# TZ10xx register map
File version: 0.1g
Registers are 32-bit, read-write, reset 0x0 unless marked. A register's access mark holds for its fields unless they carry their own. Offsets are from the block's base; [hi:lo] are bit positions.

## uart0
Base 0x40064000
Same registers: uart1 0x40065000, uart2 0x40070000
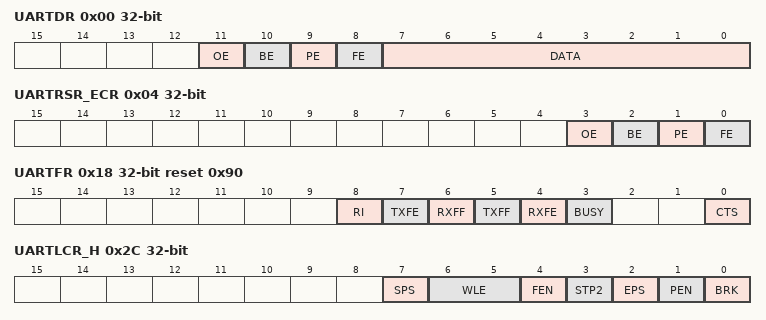
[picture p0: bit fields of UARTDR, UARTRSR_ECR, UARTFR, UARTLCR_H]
0x00 UARTDR — UART Data Register
  [11] OE ro — Overrun error 0b1: Error occurrence If FIFO is full of data at data reception and reception data becomes ready to be stored, 0b1 is stored at next FIFO fetching. The data stored in FIFO remains unchanged and reception data in the shift register used before FIFO storing is overwritten. 0b0: No error If FIFO becomes ready to store data, 0b0 is stored at next FIFO fetching.
  [10] BE ro — Break error 0b1: Error occurrence Indicates that the break condition was detected (break status: Low input equal to or greater than "reception data + status bit). In FIFO mode, 0b1 is set when the reception data for which that condition was generated comes to the highest stage. The reception data after the break condition was detected is subject to marking (High status acceptance), resulting in a wait for the next start bit detection. 0b0: No error
  [9] PE ro — Parity error 0b1: Error occurrence If the reception data does not satisfy the configured parity condition, 0b1 is set. In FIFO mode, 0b1 is set when the reception data for which that condition was generated comes to the highest stage. 0b0: No error
  [8] FE ro — Framing error 0b1: Error occurrence If the reception data does not satisfy the configured stop bit length, 0b1 is set. In FIFO mode, 0b1 is set when the reception data for which that condition was generated comes to the highest stage. 0b0: No error
  [7:0] DATA — Send and receive data At reading: Data of reception FIFO is read. At writing: Data is written to transmission FIFO. (Note) If transmission or reception is disabled midway, it stops after current data transfer is complete.
0x04 UARTRSR_ECR — UART Receive status Register/Error clear Register
  [3] OE — At reading: Overrun error 0b1: Error occurrence 0b0: No error At writing: The error flag can be cleared by writing to this register, regardless of the data value.
  [2] BE — At reading: Break error 0b1: Error occurrence 0b0: No error At writing: The error flag can be cleared by writing to this register, regardless of the data value.
  [1] PE — At reading: Parity error 0b1: Error occurrence 0b0: No error At writing: The error flag can be cleared by writing to this register, regardless of the data value.
  [0] FE — At reading: Framing error 0b1: Error occurrence 0b0: No error At writing: The error flag can be cleared by writing to this register, regardless of the data value.
0x18 UARTFR ro reset 0x90 — UART Flag Register
  [8] RI — (Ring Indicator) nUARTRI terminal status 0b1:nUARTRI = Low input status 0b0:nUARTRI = High input status
  [7] TXFE — Transmission FIFO Empty 0b1: Transmission FIFO empty (FIFO mode)/transmission retention register empty (FIFO disable) 0b0: Data existence in transmission FIFO (FIFO mode)/data existence in the transmission retention register (FIFO disable)
  [6] RXFF — Reception FIFO Full 0b1: Reception FIFO full of data (FIFO mode)/reception retention register full of data (FIFO disable) 0b0: Reception FIFO not full of data (FIFO mode)/reception retention register not full of data(FIFO disable)
  [5] TXFF — Transmission FIFO Full 0b1: Transmission FIFO full of data (FIFO mode)/transmission retention register full of data (FIFO disable) 0b0: Transmission FIFO not full of data (FIFO mode)/transmission retention register not full of data(FIFO disable)
  [4] RXFE — Reception FIFO Empty 0b1: Reception FIFO empty (FIFO mode)/reception retention register empty (FIFO disable) 0b0: Data existence in reception FIFO (FIFO mode)/data existence in the reception retention register (FIFO disable)
  [3] BUSY — Busy status 0b1: Data transmission in progress 0b0: Idle status without transmission data
  [0] CTS — nUARTCTS terminal status (Clear To Send) 0b1:nUARTCTS =Low input status 0b0:nUARTCTS =High input status
0x24 UARTIBRD — UART Integer part of the Baud Rate Divisor Register
  [15:0] BAUD_DIVINT — For baud rate generation (integer value)
0x28 UARTFBRD — UART Fractional part of the Baud Rate Divisor Register
  [5:0] BAUD_DIVFRAC — For baud rate generation (fractional value) The baud rate divisor can be obtained as follows: Baud rate divisor BAUDDIV =(FUARTCLK/(16 * baud rate) FUARTCLK is a UART reference clock frequency. BAUDDIV consists of an integer value (BAUD DIVINT) and fractional value (BAUD DIVFRAC). (Note) Transmission and reception operations are disabled if both BAUD DIVINT and BAUD DIVFRAC are set to 0x00.
0x2C UARTLCR_H — UART Line control register
  [7] SPS — Stick parity selection 0b1: Enable With PEN=1, EPS=0, and SPS=1, transmission or reception is checked with parity bit =1. With PEN=1, EPS=1, and SPS=1, transmission or reception is checked with parity bit =0. 0b0: Disable
  [6:5] WLE — Transfer bit length 0b11: 8-bit length 0b10: 7-bit length 0b01: 6-bit length 0b00: 5-bit length
  [4] FEN — FIFO enable 0b1: Enable. FIFO mode is entered. 0b0: Disable
  [3] STP2 — Stop bit length selection 0b1: 2-bit length 0b0: 1-bit length
  [2] EPS — Even parity selection 0b1: Even parity 0b0: Odd parity
  [1] PEN — Parity enable 0b1: Enable 0b0: Disable
  [0] BRK — Break transmission 0b1:Break transmission 0b0: Normal transmission (Note) Data needs to be written in the following order in setting the UARTTIBRD, UARTTFBRD, and UARTLCR_H registers. UARTLCR_H writing should be done last. (Example 1) UARTIBRD writing, UARTFBRD writing, UARTLCR_H writing (Example 2) UARTFBRD writing, UARTIBRD writing, UARTLCR_H writing
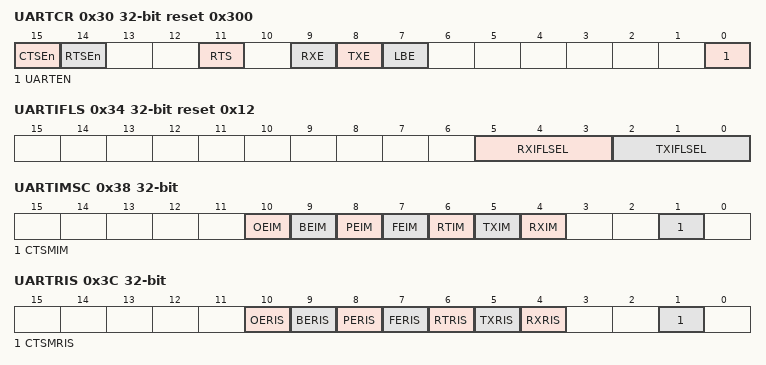
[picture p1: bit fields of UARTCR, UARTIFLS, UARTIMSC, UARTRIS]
0x30 UARTCR reset 0x300 — UART Control Register
  [15] CTSEn — CTS hardware flow control 0b1: Enable. Data is not transmitted until the nUARTCTS signal is asserted. 0b0: Disable
  [14] RTSEn — RTS hardware flow control 0b1: Enable. Data is requested only when reception FIFO contains space for receiving that data. 0b0: Disable
  [11] RTS — nUARTRTS output control 0b1:nUARTRTS=Low output 0b0:nUARTRTS=High output
  [9] RXE — Reception enable 0b1: Enable. If reception is disabled midway, it stops after data being currently received has been received. 0b0: Disable
  [8] TXE — Transmission enable 0b1: Enable. If transmission is disabled midway, it stops after data being currently transmitted has been transmitted. 0b0: Disable
  [7] LBE — Loopback enable 0b1: Enable 0b0: Disable
  [0] UARTEN — UART enable 0b1: Enable. If transmission or reception is disabled midway, it stops after completing the current transmission or reception processing. 0b0: Disable
0x34 UARTIFLS reset 0x12 — UART Interrupt FIFO Level Select Register
  [5:3] RXIFLSEL — Reception interrupt FIFO level selection (trigger occurs when FIFO becomes equal to or greater than the setting level.) 0b111 - 0b101:reserved 0b100: Reception FIFO>= 7/8 Full 0b011: Reception FIFO>= 3/4 Full 0b010: Reception FIFO>= 1/2 Full 0b001: Reception FIFO>= 1/4 Full 0b000: Reception FIFO>= 1/8 Full
  [2:0] TXIFLSEL — Transmission interrupt FIFO level selection (trigger occurs when FIFO becomes equal to or less than the setting level.) 0b111 - 0b101:reserved 0b100: Transmission FIFO<= 7/8 Full 0b011: Transmission FIFO<= 3/4 Full 0b010: Transmission FIFO<= 1/2 Full 0b001: Transmission FIFO<= 1/4 Full 0b000: Transmission FIFO<= 1/8 Full (Note) For UART, the 16byte FIFO is configured. So, each FIFO level indicates the following size. 1/8 Full = 2byte, 1/4 Full = 4byte, 1/2 Full = 8byte, 3/4 Full = 12byte, 7/8 Full = 14byte
0x38 UARTIMSC — UART Interrupt Mask Set/Clear
  [10] OEIM — Overrun error interrupt 0b1: No interrupt mask (interrupt enable) 0b0: Interrupt mask (interrupt disable)
  [9] BEIM — Break error interrupt 0b1: No interrupt mask (interrupt enable) 0b0: Interrupt mask (interrupt disable)
  [8] PEIM — Parity error interrupt 0b1: No interrupt mask (interrupt enable) 0b0: Interrupt mask (interrupt disable)
  [7] FEIM — Framing error interrupt 0b1: No interrupt mask (interrupt enable) 0b0: Interrupt mask (interrupt disable)
  [6] RTIM — Reception timeout interrupt 0b1: No interrupt mask (interrupt enable) 0b0: Interrupt mask (interrupt disable)
  [5] TXIM — Transmission interrupt 0b1: No interrupt mask (interrupt enable) 0b0: Interrupt mask (interrupt disable)
  [4] RXIM — Reception interrupt 0b1: No interrupt mask (interrupt enable) 0b0: Interrupt mask (interrupt disable)
  [1] CTSMIM — nUARTCTS modem interrupt 0b1: No interrupt mask (interrupt enable) 0b0: Interrupt mask (interrupt disable)
0x3C UARTRIS ro — UART Raw Interrupt Status Register
  [10] OERIS — Overrun error interrupt 0b1: Interrupt request available (UART interrupt occurrence before masking) 0b0: No interrupt request (UART interrupt occurrence before masking)
  [9] BERIS — Break error interrupt 0b1: Interrupt request available (UART interrupt occurrence before masking) 0b0: No interrupt request (UART interrupt occurrence before masking)
  [8] PERIS — Parity error interrupt 0b1: Interrupt request available (UART interrupt occurrence before masking) 0b0: No interrupt request (UART interrupt occurrence before masking)
  [7] FERIS — Framing error interrupt 0b1: Interrupt request available (UART interrupt occurrence before masking) 0b0: No interrupt request (UART interrupt occurrence before masking)
  [6] RTRIS — Reception timeout interrupt 0b1: Interrupt request available (UART interrupt occurrence before masking) 0b0: No interrupt request (UART interrupt occurrence before masking) (Note) Unlike other bits, RTRIS does not become 0b1 until RTIM=1 is set.
  [5] TXRIS — Transmission interrupt 0b1: Interrupt request available (UART interrupt occurrence before masking) 0b0: No interrupt request (UART interrupt occurrence before masking)
  [4] RXRIS — Reception interrupt 0b1: Interrupt request available (UART interrupt occurrence before masking) 0b0: No interrupt request (UART interrupt occurrence before masking)
  [1] CTSMRIS — nUARTCTS modem interrupt 0b1: Interrupt request available (UART interrupt occurrence before masking) 0b0: No interrupt (UART interrupt occurrence before masking) The value depends on wire connection. An interrupt request occurs every time the signal state changes.
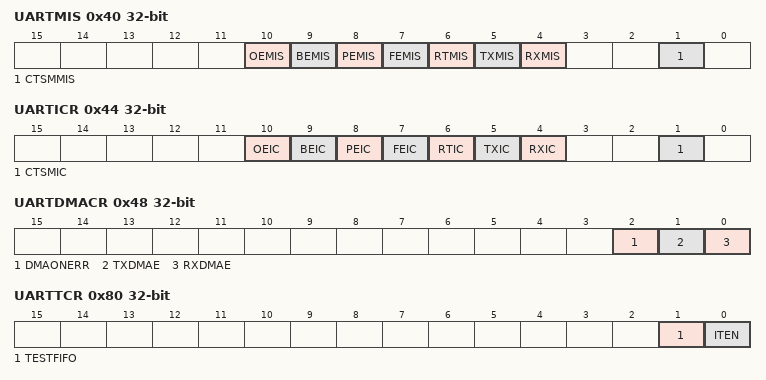
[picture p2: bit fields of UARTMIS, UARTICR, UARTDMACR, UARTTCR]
0x40 UARTMIS ro — UART Masked Interrupt Status Register
  [10] OEMIS — Overrun error interrupt
  [9] BEMIS — Break error interrupt
  [8] PEMIS — Parity error interrupt
  [7] FEMIS — Framing error interrupt
  [6] RTMIS — Reception timeout interrupt
  [5] TXMIS — Transmission interrupt
  [4] RXMIS — Reception interrupt
  [1] CTSMMIS — nUARTCTS modem interrupt
0x44 UARTICR — UART Interrupt Clear Register
  [10] OEIC — Overrun error interrupt 0b1: Interrupt request clear 0b0: No operation
  [9] BEIC — Break error interrupt 0b1: Interrupt request clear 0b0: No operation
  [8] PEIC — Parity error interrupt 0b1: Interrupt request clear 0b0: No operation
  [7] FEIC — Framing error interrupt 0b1: Interrupt request clear 0b0: No operation
  [6] RTIC — Reception timeout interrupt 0b1: Interrupt request clear 0b0: No operation
  [5] TXIC — Transmission interrupt 0b1: Interrupt request clear 0b0: No operation
  [4] RXIC — Reception interrupt 0b1: Interrupt request clear 0b0: No operation
  [1] CTSMIC — nUARTCTS modem interrupt 0b1: Interrupt request clear 0b0: No operation
0x48 UARTDMACR — UART DMA Control Register
  [2] DMAONERR — DMA on Error 0b1: Disables the DMA request if UART generates Error interrupt. 0b0: Normal operation
  [1] TXDMAE — Transmission FIFO DMA enable 0b1: DMA request enable 0b0: No DMA request
  [0] RXDMAE — Reception FIFO DMA enable 0b1: DMA request enable 0b0: No DMA request
0x80 UARTTCR — UART Test Control Register
  [1] TESTFIFO — Test FIFO enable 0b1: Test mode 0b0: Normal operation
  [0] ITEN — Integration test enable 0b1: Test mode 0b0: Normal operation
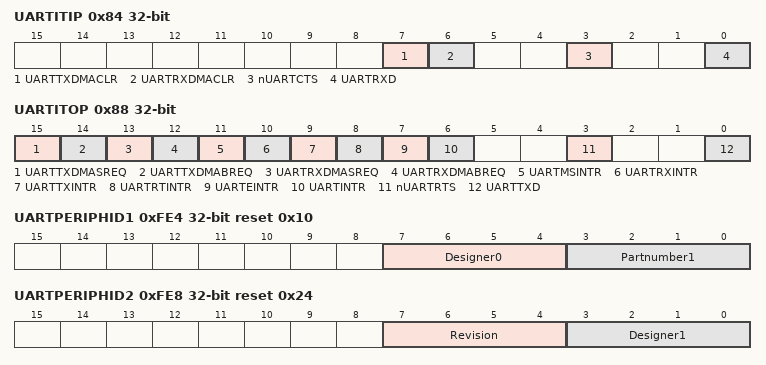
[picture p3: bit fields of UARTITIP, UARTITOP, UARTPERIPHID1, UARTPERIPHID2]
0x84 UARTITIP — UART Integration Test InPut Register
  [7] UARTTXDMACLR — AT writing, output to the UARTTXDMACLR terminal At reading, reading of the UARTTXDMACLR terminal status
  [6] UARTRXDMACLR — AT writing, output to the UARTRXDMACLR terminal At reading, reading of the UARTRXDMACLR terminal status
  [3] nUARTCTS ro — At reading, reads the nUARTCTS terminal status.
  [0] UARTRXD ro — At reading, reads the UARTRXD terminal status.
0x88 UARTITOP — UART Integration Test OutPut Register
  [15] UARTTXDMASREQ — At writing, makes output to the UARTTXDMASREQ terminal. At reading, reads the UARTTXDMASREQ terminal status.
  [14] UARTTXDMABREQ — At writing, makes output to the UARTTXDMABREQ terminal. At reading, reads the UARTTXDMABREQ terminal status.
  [13] UARTRXDMASREQ — At writing, makes output to the UARTRXDMASREQ terminal. At reading, reads the UARTRXDMASREQ terminal status.
  [12] UARTRXDMABREQ — At writing, makes output to the UARTRXDMABREQ terminal. At reading, reads the UARTRXDMABREQ terminal status.
  [11] UARTMSINTR — At writing, makes output to the UARTMSINTR terminal. At reading, reads the UARTMSINTR terminal status.
  [10] UARTRXINTR — At writing, makes output to the UARTRXINTR terminal. At reading, reads the UARTRXINTR terminal status.
  [9] UARTTXINTR — At writing, makes output to the UARTTXINTR terminal. At reading, reads the UARTTXINTR terminal status.
  [8] UARTRTINTR — At writing, makes output to the UARTRTINTR terminal. At reading, reads the UARTRTINTR terminal status.
  [7] UARTEINTR — At writing, makes output to the UARTEINTR terminal. At reading, reads the UARTEINTR terminal status.
  [6] UARTINTR — At writing, makes output to the UARTINTR terminal. At reading, reads the UARTINTR terminal status.
  [3] nUARTRTS — At writing, makes output to the nUARTRTS terminal.
  [0] UARTTXD — At writing, makes output to the UARTTXD terminal.
0x8C UARTTDR — UART Test Data Register
  [11:0] UARTTDR — At writing, data is written in reception FIFO. At reading, transmission FIFO is read.
0xFE0 UARTPERIPHID0 ro reset 0x11 — UART Peripheral ID0 Register
  [7:0] Partnumber0 — Partnumber(Lower) 011 =>11
0xFE4 UARTPERIPHID1 ro reset 0x10 — UART Peripheral ID1 Register
  [7:4] Designer0 — Designer(Lower) 41=>1
  [3:0] Partnumber1 — Partnumber(Upper) 011=>0
0xFE8 UARTPERIPHID2 ro reset 0x24 — UART Peripheral ID2 Register
  [7:4] Revision — Revision: r1p4 =>2
  [3:0] Designer1 — Designer(Upper) 41=>4
0xFEC UARTPERIPHID3 ro — UART Peripheral ID3 Register
  [7:0] Configuration — Configuration: 00
0xFF0 UARTPCELLID0 ro reset 0xD — UART PrimeCell ID0 Register
  [7:0] PCellID0 — Fixed value
0xFF4 UARTPCELLID1 ro reset 0xF0 — UART PrimeCell ID1 Register
  [7:0] PCellID1 — Fixed value
0xFF8 UARTPCELLID2 ro reset 0x5 — UART PrimeCell ID2 Register
  [7:0] PCellID2 — Fixed value
0xFFC UARTPCELLID3 ro reset 0xB1 — UART PrimeCell ID3 Register
  [7:0] PCellID3 — Fixed value
